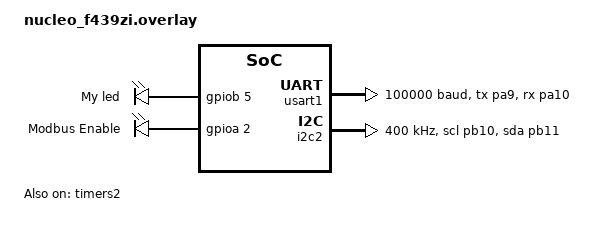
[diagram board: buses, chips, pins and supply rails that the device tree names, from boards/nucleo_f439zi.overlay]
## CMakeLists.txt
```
# SPDX-License-Identifier: Apache-2.0

cmake_minimum_required(VERSION 3.20.0)
find_package(Zephyr REQUIRED HINTS $ENV{ZEPHYR_BASE})
project(uartRs485Modbus)

target_include_directories(app PRIVATE src/uartApp
                                       src/i2cApp
                                       inc)
zephyr_include_directories(inc)
target_sources(app PRIVATE 
              src/main.c
              src/uartApp/uartApp.c
              src/i2cApp/i2cApp.c)
```

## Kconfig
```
# Copyright (c) 2024 Analog Devices, Inc.
# SPDX-License-Identifier: Apache-2.0

mainmenu "Uart Main configuration"

config UART_CLIENTNAME
	string "Client name for the Uart User"
	default "UartModbusUser"
	help
	  UART Client Name

config I2C_MAX_BUFFER_SIZE
	int "Maximum size of buffers used by i2c"
	default 6

source "Kconfig.zephyr"
```

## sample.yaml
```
sample:
  name: Modbus Slave RS485
tests:
  sample.basic.modbusSlave:
    extra_args: EXTRA_CONF_FILE="overlay-static-insecure.conf"
    tags:
      - LED
      - gpio
    depends_on: gpio, uart
    harness: led
    integration_platforms:
      - frdm_k64f
```

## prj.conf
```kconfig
CONFIG_GPIO=y
CONFIG_ADC=y
CONFIG_PWM=y
CONFIG_COUNTER=y
CONFIG_COUNTER_INIT_PRIORITY=50
CONFIG_COUNTER_TIMER_STM32=y
CONFIG_COUNTER_RTC_STM32=n
CONFIG_SERIAL=y
CONFIG_UART_ASYNC_API=y
CONFIG_TEST_RANDOM_GENERATOR=y
CONFIG_LOG=y

# I2c options
CONFIG_I2C=y
CONFIG_RTIO=y
CONFIG_I2C_RTIO=y
CONFIG_I2C_TARGET=y
CONFIG_I2C_TARGET_BUFFER_MODE=y

# Kernel options
CONFIG_MAIN_STACK_SIZE=8192
```

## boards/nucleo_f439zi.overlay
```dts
/ {
    leds {
        compatible = "gpio-leds";

        my_led: led_0 {
            gpios = <&gpiob 5 GPIO_ACTIVE_HIGH>;
            label = "My led";
        };

				modbus_en: led_1 {
						gpios = <&gpioa 2 GPIO_ACTIVE_HIGH>;
						label = "Modbus Enable";
				};
    };

    aliases {
		  led4 = &my_led;
			i2c-controller = &i2c2;
			writepin = &modbus_en;
			uart1 = &usart1;
	  };
};

&timers2 {
	status = "okay";
  st,prescaler = <10000>;
	counter1: counter {
		compatible = "st,stm32-counter";
		status = "okay";
		label = "COUNTER_2";
	};
};

&usart1 {
	pinctrl-0 = <&usart1_tx_pa9 &usart1_rx_pa10>;
	pinctrl-names = "default";
	dmas = <&dma2 7 4 STM32_DMA_PERIPH_TX STM32_DMA_FIFO_FULL>,
	       <&dma2 2 4 STM32_DMA_PERIPH_RX STM32_DMA_FIFO_FULL>;
	dma-names = "tx", "rx";
	current-speed = <100000>;
	status = "okay";
};

&i2c2 {
	pinctrl-0 = <&i2c2_scl_pb10 &i2c2_sda_pb11>;
	pinctrl-names = "default";
	status = "okay";
	clock-frequency = <400000>;
};

&dma2 {
	status = "okay";
};
```

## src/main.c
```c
/*
 * Copyright (c) 2016 Intel Corporation
 *
 * SPDX-License-Identifier: Apache-2.0
 */

#include <stdio.h>
#include <string.h>
#include <zephyr/device.h>
#include <zephyr/kernel.h>
#include "uartApp/uartApp.h"
#include "i2cApp/i2cApp.h"

/* 1000 msec = 1 sec */
#define SLEEP_TIME_MS   1000

/* The devicetree node identifier for the "led0" alias. */
#define LED0_NODE DT_ALIAS(led0)


int main(void)
{
	int rc;

	rc = uart_driverInit();
	if (rc < 0)
	{
		return 0;
	}

	rc = i2c_driverInit();
	if (rc < 0) 
	{
		return 0;
	}

	while (1) {

		k_msleep(SLEEP_TIME_MS);
	}
	return 0;
}
```
